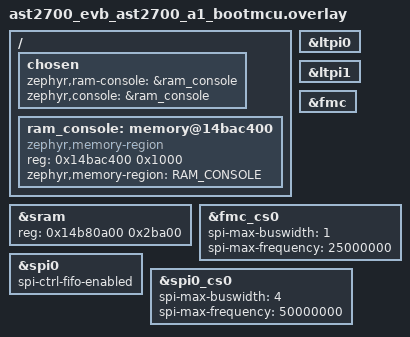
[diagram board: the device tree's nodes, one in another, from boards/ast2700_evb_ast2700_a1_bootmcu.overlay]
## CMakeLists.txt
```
# SPDX-License-Identifier: Apache-2.0

cmake_minimum_required(VERSION 3.13.1)

find_package(Zephyr HINTS $ENV{ZEPHYR_BASE})
project(ast2700_evb_full_sample)

FILE(GLOB app_sources src/*.c)

target_sources(app PRIVATE ${app_sources})
```

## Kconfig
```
# SPDX-License-Identifier: Apache-2.0
#
# Copyright (c) 2025 ASPEED Technology Inc.

config LOAD_FIT_ENABLED
	default n
	bool "Load FIT enabled"
	help
	  Load FIT enabled.

config AST_EXT_LOADER_ADDR
	hex "ASPEED external loader address"
	depends on LOAD_FIT_ENABLED
	help
	  ASPEED external loader address.

config LOAD_FIT_ADDR
	default 0x20120000
	hex "Load next FIT address"
	depends on LOAD_FIT_ENABLED
	help
	  Load next FIT address.

config IPC_SAMPLE
	default n
	bool "IPC sample enabled"
	help
	  IPC sampled enabled.

config CPTRA_SAMPLE
	default n
	bool "Caliptra mailbox command sample"
	help
	  CPTRA mailbox command sample enabled.

config CPTRA_SAMPLE_BOOTMCU
	default n
	depends on SOC_AST2700_BOOTMCU
	bool "Caliptra mailbox command sample for bootmcu"
	help
	  CPTRA mailbox command sample enabled for bootmcu.

config CPTRA_SAMPLE_SSP
	default n
	depends on SOC_AST2700_SSP || SOC_AST2700_A1_SSP
	bool "Caliptra mailbox command sample for ssp"
	help
	  CPTRA mailbox command sample enabled for ssp.

config AST2700_IROT_LOAD_IMAGE
	default n
	depends on SOC_AST2700_SSP || SOC_AST2700_A1_SSP
	bool "Load CA35 boot images"
	help
	  Load CA35 image from fixed flash offset to DRAM.

source "Kconfig.zephyr"
```

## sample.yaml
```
sample:
  name: Aspeed demo sample
tests:
  sample.board.ast2700_evb:
    platform_allow: ast2700_evb
```

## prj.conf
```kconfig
CONFIG_LOG=y
CONFIG_LOG_MODE_IMMEDIATE=y
CONFIG_LOG_ALWAYS_RUNTIME=y
CONFIG_LOG_DEFAULT_LEVEL=2
# CONFIG_LOAD_FIT_ENABLED=y
CONFIG_AST_EXT_LOADER_ADDR=0x14b9e000
CONFIG_LOAD_FIT_ADDR=0x20120000
CONFIG_IPC_SAMPLE=y
CONFIG_LTPI=y
CONFIG_MAIN_STACK_SIZE=6144
CONFIG_RAM_CONSOLE=y
```

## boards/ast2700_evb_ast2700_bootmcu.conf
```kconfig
CONFIG_CPTRA_SAMPLE_BOOTMCU=y
CONFIG_MAIN_STACK_SIZE=16384
CONFIG_MBEDTLS=y
CONFIG_MBEDTLS_SHA384=y
CONFIG_SYS_CLOCK_TICKS_PER_SEC=1000
CONFIG_OTP_AST27XX=y
```

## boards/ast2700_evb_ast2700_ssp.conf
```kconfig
CONFIG_WATCHDOG=y
CONFIG_SHELL=y
CONFIG_LOG_BACKEND_UART=y
CONFIG_SHELL_LOG_BACKEND=n
CONFIG_SHELL_STACK_SIZE=6144
CONFIG_COMMON_LIBC_MALLOC_ARENA_SIZE=16384
CONFIG_HEAP_MEM_POOL_SIZE=16384
CONFIG_LOG_DEFAULT_LEVEL=3
CONFIG_MISC_ASPEED_LOG_LEVEL_INF=y
CONFIG_CPTRA_SAMPLE_SSP=y
CONFIG_FLASH=y
CONFIG_SPI=y
CONFIG_SPI_NOR_MULTI_DEV=y
CONFIG_SPI_ASPEED=y
CONFIG_SPI_DMA_SUPPORT_ASPEED=y
CONFIG_FLASH_PAGE_LAYOUT=y
# CONFIG_SPI_NOR is not set
CONFIG_FLASH_MAP=y
CONFIG_FLASH_SHELL=y
CONFIG_AST2700_IROT_LOAD_IMAGE=y
CONFIG_SPI_MONITOR_ASPEED=y
CONFIG_SPI_MONITOR_SHELL_ASPEED=y
CONFIG_ASPEED_SPIM_LOG_SIZE=0
```

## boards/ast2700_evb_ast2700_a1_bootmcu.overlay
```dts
&ltpi0{
	status = "okay";
};

&ltpi1{
	status = "okay";
};

/ {
	chosen {
		zephyr,ram-console = &ram_console;
		zephyr,console = &ram_console;
	};

	ram_console: memory@14bac400 {
		compatible = "zephyr,memory-region";
		reg = <0x14bac400 0x1000>;
		zephyr,memory-region = "RAM_CONSOLE";
	};
};

&sram {
	reg = <0x14b80a00 0x2ba00>;
};

&fmc {
	status = "okay";
};

&fmc_cs0 {
	status = "okay";
	spi-max-buswidth = <1>;
	spi-max-frequency = <25000000>;
};

&spi0 {
	status = "okay";
	spi-ctrl-fifo-enabled;
};

&spi0_cs0 {
	status = "okay";
	spi-max-buswidth = <4>;
	spi-max-frequency = <50000000>;
};
```

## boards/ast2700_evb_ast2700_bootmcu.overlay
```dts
&ltpi0{
	status = "okay";
};

&ltpi1{
	status = "okay";
};

/ {
	chosen {
		zephyr,ram-console = &ram_console;
		zephyr,console = &ram_console;
	};

	ram_console: memory@14b8a000 {
		compatible = "zephyr,memory-region";
		reg = <0x14b8a000 0x1000>;
		zephyr,memory-region = "RAM_CONSOLE";
	};

	sram: memory@14ba8000 {
		reg = <0x14ba8000 0x17800>;
	};
};

&fmc {
	status = "okay";
};

&fmc_cs0 {
	status = "okay";
	spi-max-buswidth = <1>;
	spi-max-frequency = <25000000>;
};

&spi0 {
	status = "okay";
	spi-ctrl-fifo-enabled;
};

&spi0_cs0 {
	status = "okay";
	spi-max-buswidth = <4>;
	spi-max-frequency = <50000000>;
};
```

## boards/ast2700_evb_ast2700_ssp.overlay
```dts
#include <zephyr/dt-bindings/spi/ast2700_spim.h>

&spim0 {
	status = "okay";
};

&spim1 {
	allow-cmds = [03 13 0b 0c 6b 6c 01 05 35 06 04 20 21 9f 5a b7 e9 32 34 d8 dc 02 12 3b 3c
				  70 50 eb ec c2];
	addr-priv-configs = <>;
	status = "okay";
};
```

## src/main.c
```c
/*
 * Copyright 2021 ASPEED
 *
 * SPDX-License-Identifier: Apache-2.0
 */

#include <soc.h>
#include <zephyr/kernel.h>
#include <zephyr/drivers/ipm.h>
#include <zephyr/sys/printk.h>
#include <zephyr/drivers/misc/aspeed/cptra_ipc.h>
#include <zephyr/drivers/misc/aspeed/ltpi_ipc.h>
#include <string.h>
#if defined(CONFIG_IPC_SAMPLE)
#include "ipc_sample.h"
#endif
#if defined(CONFIG_CPTRA_SAMPLE)
#include "cptra_sample.h"
#endif
#include "cptra_idevid.h"
#if defined(CONFIG_SPI_MONITOR_ASPEED)
#include "spim_sample.h"
#endif

int aspeed_load_image(void);

int main(void)
{
	int rc = 0;

	printk("%s demo (%s - %s)\n", CONFIG_BOARD, __DATE__, __TIME__);

#if defined(CONFIG_LOAD_FIT_ENABLED)
	void *func = (void *)CONFIG_AST_EXT_LOADER_ADDR;
	((void (*)(uint32_t))func)((uint32_t)CONFIG_LOAD_FIT_ADDR);
#endif

#if defined(CONFIG_SPI_MONITOR_ASPEED)
	sipm_demo();
#endif

#if defined(CONFIG_CPTRA_IPC) || defined(CONFIG_CPTRA_IPC_SSP)
	cptra_ipc_enable();
#endif

#if defined(CONFIG_LTPI_IPC)
	ltpi_ipc_enable();
#endif

#if defined(CONFIG_IPC_SAMPLE)
	ipc_test();
#endif

#if defined(CONFIG_CPTRA_SAMPLE)
	cptra_test();
#endif

#if defined(CONFIG_AST2700_IROT_LOAD_IMAGE)
	aspeed_load_image();
#endif

#if defined(CONFIG_SOC_AST2700_BOOTMCU)
	/* Populate IDEVID Certificate */
	cptra_populate_idevid();
#endif

	return rc;
}
```

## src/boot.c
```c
/*
 * SPDX-License-Identifier: Apache-2.0
 *
 * Copyright (c) 2025 ASPEED Technology Inc.
 */

#include <zephyr/drivers/flash.h>
#include <zephyr/kernel.h>
#include <zephyr/sys/util.h>
#include <soc.h>
#include <stdlib.h>
#include <string.h>
#include <zephyr/kernel.h>

#define LOG_MODULE_NAME boot_demo

#include <zephyr/logging/log.h>
LOG_MODULE_REGISTER(LOG_MODULE_NAME);

#define ASPEED_CPU_CA35_RVBAR0 (0x12C02110 + 0x60000000)
#define ASPEED_CPU_CA35_RVBAR1 (0x12C02114 + 0x60000000)
#define ASPEED_CPU_CA35_RVBAR2 (0x12C02118 + 0x60000000)
#define ASPEED_CPU_CA35_RVBAR3 (0x12C0211c + 0x60000000)

#define ASPEED_CPU_SMP_EP0 (0x12C02780 + 0x60000000)
#define ASPEED_CPU_SMP_EP1 (0x12C02788 + 0x60000000)
#define ASPEED_CPU_SMP_EP2 (0x12C02790 + 0x60000000)
#define ASPEED_CPU_SMP_EP3 (0x12C02798 + 0x60000000)

#define ASPEED_CPU_CA35_REL (0x12C0210C + 0x60000000)

struct image_info {
	char *name;
	uint32_t dst;
	uint32_t src;
	uint32_t len;
};

struct image_info image_tbl[] = {
	{"ATF", 0x04000000, 0x00200000, 0x10000},    /* 64KB */
	{"UBOOT", 0x05880000, 0x00210000, 0x100000}, /* 1MB */
	{"TEE", 0x04080000, 0x00310000, 0x80000},    /* 512KB */
};

void aspeed_prepare_for_boot(void)
{
	/* Given CA35 reset vector */
	sys_write32(0x43000000, ASPEED_CPU_CA35_RVBAR0);
	sys_write32(0x43000000, ASPEED_CPU_CA35_RVBAR1);
	sys_write32(0x43000000, ASPEED_CPU_CA35_RVBAR2);
	sys_write32(0x43000000, ASPEED_CPU_CA35_RVBAR3);

	sys_write32(0x00000000, ASPEED_CPU_SMP_EP0);
	sys_write32(0x00000004, ASPEED_CPU_SMP_EP0 + 4);
	sys_write32(0x00000000, ASPEED_CPU_SMP_EP1);
	sys_write32(0x00000000, ASPEED_CPU_SMP_EP1 + 4);
	sys_write32(0x00000000, ASPEED_CPU_SMP_EP2);
	sys_write32(0x00000000, ASPEED_CPU_SMP_EP2 + 4);
	sys_write32(0x00000000, ASPEED_CPU_SMP_EP3);
	sys_write32(0x00000000, ASPEED_CPU_SMP_EP3 + 4);

	/* Release CA35 */
	sys_write32(1, ASPEED_CPU_CA35_REL);
}

int aspeed_load_image(void)
{
	const struct device *flash_dev;
	uint32_t dst;
	uint32_t src;
	uint32_t len;
	uint32_t ret;
	int i;

	flash_dev = device_get_binding("fmc@0");
	if (!flash_dev) {
		LOG_ERR("No device named fmc@0.");
		return -ENXIO;
	}

	LOG_INF("Loading images...");

	for (i = 0; i < ARRAY_SIZE(image_tbl); i++) {
		LOG_INF("Image[%d]: %s", i, image_tbl[i].name);

		dst = image_tbl[i].dst;
		src = image_tbl[i].src;
		len = image_tbl[i].len;

		ret = flash_read(flash_dev, src, (void *)dst, len);
		if (ret) {
			LOG_ERR("fail to read %s from flash fmc@0", image_tbl[i].name);
			return -1;
		}
	}

	aspeed_prepare_for_boot();

	return 0;
}
```

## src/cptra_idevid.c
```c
/*
 * SPDX-License-Identifier: Apache-2.0
 *
 * Copyright (c) 2025 ASPEED Technology Inc.
 */

#include <zephyr/drivers/cptra.h>
#include <zephyr/logging/log.h>
#include <zephyr/drivers/misc/aspeed/otp_ast27xx.h>
#include <zephyr/sys/byteorder.h>

LOG_MODULE_REGISTER(cptra_idevid, CONFIG_SOC_LOG_LEVEL);

#if defined(CONFIG_CPTRA_DICE)
#define CPTRA_DICE_DRV_NAME			DEVICE_DT_NAME(DT_INST(0, aspeed_cptra_dice))
#else
#define CPTRA_DICE_DRV_NAME			"aspeed_cptra_dice"
#endif

#define OTPCAL_IDEVID_TBS_OFFSET		0x62
#define OTPCAL_IDEVID_SIGN_OFFSET		0x262

static int cptra_get_idevid_cert(struct cptra_get_idev_cert_ia *input,
				 struct cptra_get_idev_cert_oa *output)
{
#if defined(CONFIG_CPTRA_DICE)
	const struct device *dev = device_get_binding(CPTRA_DICE_DRV_NAME);
#else
	const struct device *dev = NULL;
#endif
	uint16_t *p16 = (uint16_t *)input->tbs;
	uint32_t tbs_offset = OTPCAL_IDEVID_TBS_OFFSET;
	uint32_t cert_offset = OTPCAL_IDEVID_SIGN_OFFSET;
	int size; /* word */
	int tbs_size = 0;
	int ret;

	if (!dev) {
		LOG_ERR("Device %s not found", CPTRA_DICE_DRV_NAME);
		return -ENODEV;
	}

	memset(input, 0, sizeof(struct cptra_get_idev_cert_ia));
	memset(output, 0, sizeof(struct cptra_get_idev_cert_oa));

	for (int i = 0; i < sizeof(input->tbs) / 2; i++) {
		ret = otp_read_cptra(tbs_offset + i, p16);
		if (ret) {
			LOG_ERR("otp_read_cptra failed, ret:0x%x", ret);
			goto end;
		}

		if (i == 1) {
			tbs_size = sys_cpu_to_be16(*p16);
		}

		if (*p16++ == 0x0) {
			if (i == 0) {
				LOG_ERR("tbs is empty");
				ret = -EIO;
				goto end;
			}

			/* Read tbs until end mark 0x0 */
			size = i + 1;
			break;
		}
	}

	input->tbs_size = tbs_size + 0x4; /* 4 bytes for DER TAG & LENGTH */
	/* LOG_HEXDUMP_INF(input->tbs, input->tbs_size, "tbs"); */

	p16 = (uint16_t *)input->signature_r;
	for (int i = 0; i < sizeof(input->signature_r) / 2; i++) {
		ret = otp_read_cptra(cert_offset + i, p16++);
		if (ret) {
			LOG_ERR("otp_read_cptra failed, ret:0x%x", ret);
			goto end;
		}
	}

	cert_offset += 0x18; /* 48 bytes for r */
	p16 = (uint16_t *)input->signature_s;
	for (int i = 0; i < sizeof(input->signature_s) / 2; i++) {
		ret = otp_read_cptra(cert_offset + i, p16++);
		if (ret) {
			LOG_ERR("otp_read_cptra failed, ret:0x%x", ret);
			goto end;
		}
	}

	/* LOG_HEXDUMP_INF(input->signature_r, sizeof(input->signature_r), "r:"); */
	/* LOG_HEXDUMP_INF(input->signature_s, sizeof(input->signature_s), "s:"); */

	ret = caliptra_get_idev_cert(dev, input, output);
	if (ret) {
		LOG_ERR("caliptra_get_idev_cert is failure, ret:0x%x", ret);
		goto end;
	} else
		LOG_DBG("caliptra_get_idev_cert is successful");

	LOG_DBG("output: chksum:0x%x, fips_status:0x%x",
		output->chksum, output->fips_status);
	LOG_HEXDUMP_DBG(output->cert, output->cert_size, "cert:");

	return 0;

end:
	return ret;
}

int cptra_populate_idevid(void)
{
#if defined(CONFIG_CPTRA_DICE)
	const struct device *dev = device_get_binding(CPTRA_DICE_DRV_NAME);
#else
	const struct device *dev = NULL;
#endif
	struct cptra_get_idev_cert_ia input;
	struct cptra_get_idev_cert_oa output;
	struct cptra_populate_idev_cert_ia in_buff;
	struct cptra_populate_idev_cert_oa out_buff;
	int ret;

	if (!dev) {
		LOG_ERR("Device %s not found", CPTRA_DICE_DRV_NAME);
		return -ENODEV;
	}

	/* Get IDEVID Certificate */
	ret = cptra_get_idevid_cert(&input, &output);
	if (ret)
		return ret;

	/* Populate IDEVID Certificate */
	LOG_INF("Populate IDEVID Certificate...");

	memset(&in_buff, 0, sizeof(struct cptra_populate_idev_cert_ia));
	memset(&out_buff, 0, sizeof(struct cptra_populate_idev_cert_oa));

	/* Initial idevid cert */
	in_buff.cert_size = output.cert_size;
	memcpy(in_buff.cert, output.cert, output.cert_size);

	ret = caliptra_populate_idev_cert(dev, &in_buff, &out_buff);
	if (ret) {
		LOG_ERR("caliptra_populate_idev_cert is failure, ret:0x%x", ret);
		goto end;
	} else
		LOG_DBG("caliptra_populate_idev_cert is successful");

	LOG_DBG("output: chksum:0x%x, fips_status:0x%x",
		out_buff.chksum, out_buff.fips_status);

	if (out_buff.fips_status) {
		LOG_ERR("FIPS status is not zero, fips_status:0x%x",
			out_buff.fips_status);
		ret = -EIO;
		goto end;
	}

	LOG_INF("%s: Pass", __func__);
	return 0;

end:
	LOG_ERR("%s: Failed", __func__);
	return ret;
}
```

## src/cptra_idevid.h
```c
/*
 * SPDX-License-Identifier: Apache-2.0
 *
 * Copyright (c) 2025 ASPEED Technology Inc.
 */

#ifndef CPTRA_IDEVID_H_
#define CPTRA_IDEVID_H_

int cptra_populate_idevid(void);

#endif
```

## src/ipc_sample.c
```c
/*
 * SPDX-License-Identifier: Apache-2.0
 *
 * Copyright (c) 2024 ASPEED Technology Inc.
 */

#include <soc.h>
#include <zephyr/kernel.h>
#include <zephyr/logging/log.h>
#include <zephyr/drivers/ipm.h>

LOG_MODULE_REGISTER(ipc_test, CONFIG_SOC_LOG_LEVEL);

#define DEFAULT_LINE_LENGTH_BYTES	(16)
#define IPC_DEV_SSP_BOOTMCU		"ipc1@400"
#define IPC_CHANNEL_ID			0

static void ch0_ipm_cb(const struct device *ipmdev, void *user_data,
		       uint32_t id, volatile void *msg_data)
{
	int i;
	int width = 4;
	int linelen = DEFAULT_LINE_LENGTH_BYTES / width;
	int max_msg_data_size = ipm_max_data_size_get(ipmdev);
	uint32_t *buf = (uint32_t *)msg_data;

	LOG_INF("%s:msg id %x, msg data at %p, msg size 0x%x\n",
		__func__, id, msg_data, max_msg_data_size);
	while (max_msg_data_size) {
		LOG_INF("%p:", buf);

		for (i = 0; i < linelen; i++)
			LOG_INF(" %08x ", buf[i]);
		LOG_INF("\n");
		buf += linelen;
		max_msg_data_size -= linelen * width;
	}

	max_msg_data_size = ipm_max_data_size_get(ipmdev);
	ipm_send(ipmdev, 0, id, (void *)msg_data, max_msg_data_size);
}

int ipc_test(void)
{
	char ipc_name[32] = IPC_DEV_SSP_BOOTMCU;
	int device_id = IPC_CHANNEL_ID;
	const struct device *ipmdev;
	int rc;

	LOG_INF("%s", __func__);

	ipmdev = device_get_binding(ipc_name);
	if (!ipmdev) {
		LOG_ERR("%s: device_get_binding failed to find device\n", ipc_name);
		rc = 1;
		return rc;
	}

	ipm_register_id_callback(ipmdev, device_id, ch0_ipm_cb, NULL);
	rc = ipm_set_id_enabled(ipmdev, device_id, 1);
	if (rc) {
		LOG_ERR("%s: cannot ipm_set_enabled\n", ipc_name);
		rc = 1;
		return rc;
	}

	return 0;
}
```

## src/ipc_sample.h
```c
/*
 * SPDX-License-Identifier: Apache-2.0
 *
 * Copyright (c) 2025 ASPEED Technology Inc.
 */

#ifndef IPC_SAMPLE_H_
#define IPC_SAMPLE_H_

int ipc_test(void);

#endif /* IPC_SAMPLE_H_ */
```

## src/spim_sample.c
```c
/*
 * SPDX-License-Identifier: Apache-2.0
 *
 * Copyright (c) 2026 ASPEED Technology Inc.
 */

#include <soc.h>
#include <string.h>
#include <zephyr/kernel.h>
#include <zephyr/sys/printk.h>
#include <zephyr/drivers/misc/aspeed/ast2700_spim.h>

void sipm_demo(void)
{
	const struct device *spim_dev = device_get_binding("spim@1");

	spim_isr_callback_install(spim_dev, ast2700_spim_blocked_log_parser);
}
```

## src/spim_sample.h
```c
/*
 * SPDX-License-Identifier: Apache-2.0
 *
 * Copyright (c) 2026 ASPEED Technology Inc.
 */

#ifndef _SPIM_SAMPLE_H_
#define _SPIM_SAMPLE_H_

void sipm_demo(void);

#endif /* _SPIM_SAMPLE_H_ */
```
